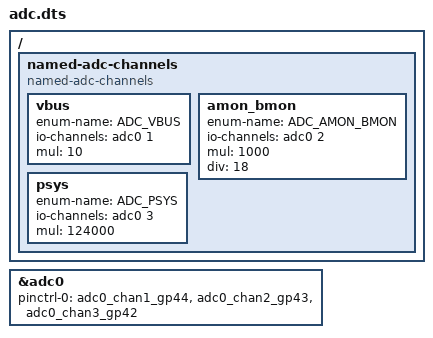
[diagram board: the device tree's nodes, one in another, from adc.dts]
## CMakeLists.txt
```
# Copyright 2021 The ChromiumOS Authors
# Use of this source code is governed by a BSD-style license that can be
# found in the LICENSE file.

cmake_minimum_required(VERSION 3.13.1)

find_package(Zephyr REQUIRED HINTS "${ZEPHYR_BASE}")

cros_ec_library_include_directories(include)

# Common Herobrine implementation
zephyr_library_sources(
  "src/board_chipset.c"
)

# Board specific implementation
zephyr_library_sources_ifdef(CONFIG_PLATFORM_EC_USBC
  "src/usbc_config.c"
  "src/usb_pd_policy.c")
zephyr_library_sources_ifdef(CONFIG_PLATFORM_EC_I2C
  "src/i2c.c")

if(DEFINED CONFIG_BOARD_EVOKER)
	project(evoker)
	zephyr_library_sources(
		"evoker/src/charger_override.c"
	)
elseif(DEFINED CONFIG_BOARD_HEROBRINE)
	project(herobrine)
	zephyr_library_sources_ifdef(CONFIG_PLATFORM_EC_USBC
	  "src/herobrine/alt_dev_replacement.c")
elseif(DEFINED CONFIG_BOARD_HOGLIN)
	project(hoglin)
elseif(DEFINED CONFIG_BOARD_VILLAGER)
	zephyr_library_sources(
		"villager/src/keyboard.c"
	)
	project(villager)
elseif(DEFINED CONFIG_BOARD_ZOGLIN)
	project(zoglin)
elseif(DEFINED CONFIG_BOARD_ZOMBIE)
	project(zombie)
endif()
```

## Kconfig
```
# Copyright 2022 The Chromium OS Authors. All rights reserved.
# Use of this source code is governed by a BSD-style license that can be
# found in the LICENSE file.

config BOARD_EVOKER
	bool "Evoker Board"
	help
	  Build the Evoker board. The board is based on the Herobrine
	  reference design.

config BOARD_HEROBRINE
	bool "Google Herobrine Baseboard"
	help
	  Build Google Herobrine reference board.  The board uses Nuvoton
	  NPCX9 chip as the EC.

config BOARD_HOGLIN
	bool "Qualcomm Hoglin Baseboard"
	help
	  Build Qualcomm Hoglin reference board.  The board uses Nuvoton
	  NPCX9 chip as the EC.

config BOARD_VILLAGER
	bool "Villager Board"
	help
	  Build the Villager board. The board is based on the Herobrine
	  reference design.

config BOARD_ZOGLIN
	bool "Qualcomm Zoglin Baseboard"
	help
	  Build Qualcomm Hoglin reference board.  The board uses Nuvoton
	  NPCX9 chip as the EC.

source "Kconfig.zephyr"
```

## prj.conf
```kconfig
# Copyright 2021 The ChromiumOS Authors
# Use of this source code is governed by a BSD-style license that can be
# found in the LICENSE file.

CONFIG_CROS_EC=y
CONFIG_SHIMMED_TASKS=y
CONFIG_PLATFORM_EC=y
CONFIG_PLATFORM_EC_BRINGUP=y
CONFIG_PLATFORM_EC_EXTPOWER_GPIO=y
CONFIG_PLATFORM_EC_SWITCH=y
CONFIG_PLATFORM_EC_LID_SWITCH=y
CONFIG_PLATFORM_EC_BACKLIGHT_LID=y
CONFIG_PLATFORM_EC_POWER_BUTTON=y
CONFIG_PLATFORM_EC_CBI_GPIO=y
CONFIG_KERNEL_SHELL=y
CONFIG_PLATFORM_EC_BOARD_RESET_AFTER_POWER_ON=y

# I2C options
CONFIG_I2C=y
CONFIG_PLATFORM_EC_CONSOLE_CMD_I2C_SPEED=y
CONFIG_PLATFORM_EC_HOSTCMD_I2C_CONTROL=y

# Shell history and tab autocompletion (for convenience)
CONFIG_SHELL_HELP=y
CONFIG_SHELL_HISTORY=y
CONFIG_SHELL_TAB=y
CONFIG_SHELL_TAB_AUTOCOMPLETION=y

# Application Processor is Qualcomm SC7280
CONFIG_AP_ARM_QUALCOMM_SC7280=y

# GPIO Switchcap
CONFIG_PLATFORM_EC_SWITCHCAP_GPIO=y

# Board version is selected over GPIO board ID pins.
CONFIG_PLATFORM_EC_BOARD_VERSION_GPIO=y

# Power Sequencing
CONFIG_PLATFORM_EC_POWERSEQ=y
CONFIG_PLATFORM_EC_POWERSEQ_HOST_SLEEP=y
CONFIG_PLATFORM_EC_POWERSEQ_PP5000_CONTROL=n
CONFIG_PLATFORM_EC_POWER_SLEEP_FAILURE_DETECTION=y
CONFIG_PLATFORM_EC_CHIPSET_RESET_HOOK=y
CONFIG_PLATFORM_EC_CHIPSET_RESUME_INIT_HOOK=y

# MKBP event
CONFIG_PLATFORM_EC_MKBP_EVENT=y
CONFIG_PLATFORM_EC_MKBP_USE_GPIO=y

# Keyboard
CONFIG_PLATFORM_EC_KEYBOARD=y
CONFIG_PLATFORM_EC_KEYBOARD_PROTOCOL_MKBP=y
CONFIG_PLATFORM_EC_MKBP_INPUT_DEVICES=y
CONFIG_PLATFORM_EC_KEYBOARD_COL2_INVERTED=y
CONFIG_PLATFORM_EC_KEYBOARD_REFRESH_ROW3=y
CONFIG_PLATFORM_EC_VOLUME_BUTTONS=y
CONFIG_PLATFORM_EC_CMD_BUTTON=y
CONFIG_CROS_KB_RAW_NPCX=y

# ADC
CONFIG_ADC=y
CONFIG_ADC_SHELL=n

# Battery
CONFIG_PLATFORM_EC_BATTERY=y
CONFIG_PLATFORM_EC_BATTERY_SMART=y
CONFIG_PLATFORM_EC_I2C_VIRTUAL_BATTERY=y
CONFIG_PLATFORM_EC_I2C_PASSTHRU_RESTRICTED=y
CONFIG_PLATFORM_EC_BATTERY_FUEL_GAUGE=y
CONFIG_PLATFORM_EC_BATTERY_CUT_OFF=y
CONFIG_PLATFORM_EC_BATTERY_PRESENT_GPIO=y
CONFIG_PLATFORM_EC_CHARGER_ISL9238C=y
CONFIG_PLATFORM_EC_CHARGE_RAMP_HW=y
CONFIG_PLATFORM_EC_USE_BATTERY_DEVICE_CHEMISTRY=y
CONFIG_PLATFORM_EC_BATTERY_DEVICE_CHEMISTRY="LION"
CONFIG_PLATFORM_EC_BATTERY_REVIVE_DISCONNECT=y
CONFIG_PLATFORM_EC_CHARGER_DISCHARGE_ON_AC=y
CONFIG_PLATFORM_EC_CHARGER_DISCHARGE_ON_AC_CHARGER=y
CONFIG_PLATFORM_EC_CHARGER_MIN_BAT_PCT_FOR_POWER_ON=2
CONFIG_PLATFORM_EC_CHARGER_MIN_POWER_MW_FOR_POWER_ON=12500
CONFIG_PLATFORM_EC_CHARGER_PROFILE_OVERRIDE=y
CONFIG_PLATFORM_EC_CHARGER_PSYS=y
CONFIG_PLATFORM_EC_CHARGER_PSYS_READ=y
CONFIG_PLATFORM_EC_CHARGER_SENSE_RESISTOR=10
CONFIG_PLATFORM_EC_CHARGER_SENSE_RESISTOR_AC=20
CONFIG_PLATFORM_EC_CONSOLE_CMD_CHARGER_ADC_AMON_BMON=y

# USB-A
CONFIG_PLATFORM_EC_USBA=y

# USB-C
CONFIG_PLATFORM_EC_USB_PD_FRS=y
CONFIG_PLATFORM_EC_BC12_DETECT_PI3USB9201=y
CONFIG_PLATFORM_EC_USB_PD_USB32_DRD=n
CONFIG_PLATFORM_EC_USBC_PPC_SYV682C=y
CONFIG_PLATFORM_EC_USB_PD_FRS_PPC=y
CONFIG_PLATFORM_EC_USBC_RETIMER_FW_UPDATE=n
CONFIG_PLATFORM_EC_USBC_SS_MUX_DFP_ONLY=y
CONFIG_PLATFORM_EC_USB_DRP_ACC_TRYSRC=y
CONFIG_PLATFORM_EC_USB_PD_5V_EN_CUSTOM=y
CONFIG_PLATFORM_EC_USB_PD_VBUS_DETECT_TCPC=y
CONFIG_PLATFORM_EC_USB_PD_DISCHARGE_PPC=y
CONFIG_PLATFORM_EC_USB_PD_DPS=y
CONFIG_PLATFORM_EC_USB_PD_REV30=y
CONFIG_PLATFORM_EC_USB_PD_TBT_COMPAT_MODE=n
CONFIG_PLATFORM_EC_USB_PD_USB4=n
CONFIG_PLATFORM_EC_USB_PD_TCPC_LOW_POWER=y
CONFIG_PLATFORM_EC_USB_PD_TCPM_PS8805=y
CONFIG_PLATFORM_EC_USB_PD_TCPC_RUNTIME_CONFIG=n
CONFIG_PLATFORM_EC_USB_MUX_RUNTIME_CONFIG=n
CONFIG_PLATFORM_EC_USB_PD_LOGGING=y
CONFIG_PLATFORM_EC_CONFIG_USB_PD_3A_PORTS=2

# USB ID
# This is allocated specifically for Herobrine
# http://google3/hardware/standards/usb/
# TODO(b/183608112): Move to device tree
CONFIG_PLATFORM_EC_USB_PID=0x5055

# RTC
CONFIG_PLATFORM_EC_RTC=y
CONFIG_CROS_RTC_NXP_PCF85063A=y
CONFIG_PLATFORM_EC_HOSTCMD_RTC=y
CONFIG_PLATFORM_EC_CONSOLE_CMD_RTC=y
CONFIG_PLATFORM_EC_CONSOLE_CMD_RTC_ALARM=y

# EC software sync
CONFIG_PLATFORM_EC_VBOOT_HASH=y

# Sensors
CONFIG_PLATFORM_EC_MOTIONSENSE=y
CONFIG_PLATFORM_EC_ACCEL_FIFO=y
CONFIG_PLATFORM_EC_ACCEL_SPOOF_MODE=y
CONFIG_PLATFORM_EC_CONSOLE_CMD_ACCELS=y
CONFIG_PLATFORM_EC_CONSOLE_CMD_ACCEL_INFO=y
CONFIG_PLATFORM_EC_GMR_TABLET_MODE=y
CONFIG_PLATFORM_EC_LID_ANGLE=y
CONFIG_PLATFORM_EC_LID_ANGLE_UPDATE=y
CONFIG_PLATFORM_EC_SENSOR_TIGHT_TIMESTAMPS=y
CONFIG_PLATFORM_EC_TABLET_MODE=y
CONFIG_PLATFORM_EC_TABLET_MODE_SWITCH=y
CONFIG_PLATFORM_EC_MAX_SENSOR_FREQ_MILLIHZ=100000

# Sensor Drivers
CONFIG_PLATFORM_EC_ACCEL_BMA255=y
CONFIG_PLATFORM_EC_ACCELGYRO_BMI260=y
CONFIG_PLATFORM_EC_ACCELGYRO_BMI_COMM_I2C=y

CONFIG_SYSCON=y
CONFIG_PLATFORM_EC_EMULATED_SYSRQ=y
```

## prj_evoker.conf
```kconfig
# Copyright 2022 The ChromiumOS Authors
# Use of this source code is governed by a BSD-style license that can be
# found in the LICENSE file.

# Evoker board-specific Kconfig settings.
CONFIG_BOARD_EVOKER=y

# Disable type-c port sourcing 3A
CONFIG_PLATFORM_EC_CONFIG_USB_PD_3A_PORTS=0

CONFIG_PLATFORM_EC_ACCEL_BMA255=n
CONFIG_PLATFORM_EC_ACCEL_BMA4XX=y

CONFIG_PLATFORM_EC_CONSOLE_CMD_CHARGER_DUMP=y
```

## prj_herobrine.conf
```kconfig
# Copyright 2022 The ChromiumOS Authors. All rights reserved.
# Use of this source code is governed by a BSD-style license that can be
# found in the LICENSE file.

# Herobrine-NPCX9 reference-board-specific Kconfig settings.
CONFIG_BOARD_HEROBRINE=y

# Sensors
CONFIG_PLATFORM_EC_ALS=y

# Sensor Drivers
CONFIG_PLATFORM_EC_ALS_TCS3400=y
CONFIG_PLATFORM_EC_ALS_TCS3400_EMULATED_IRQ_EVENT=y
```

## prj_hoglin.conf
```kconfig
# Copyright 2022 The ChromiumOS Authors. All rights reserved.
# Use of this source code is governed by a BSD-style license that can be
# found in the LICENSE file.

# Hoglin reference-board-specific Kconfig settings.
CONFIG_BOARD_HOGLIN=y
CONFIG_PLATFORM_EC_ACCEL_BMA255=n
CONFIG_PLATFORM_EC_ACCEL_BMA4XX=y

# Sensors
CONFIG_PLATFORM_EC_ALS=y

# Sensor Drivers
CONFIG_PLATFORM_EC_ALS_TCS3400=y
CONFIG_PLATFORM_EC_ALS_TCS3400_EMULATED_IRQ_EVENT=y
```

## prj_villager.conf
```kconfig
# Copyright 2022 The ChromiumOS Authors. All rights reserved.
# Use of this source code is governed by a BSD-style license that can be
# found in the LICENSE file.

# Villager board-specific Kconfig settings.
CONFIG_BOARD_VILLAGER=y

CONFIG_PLATFORM_EC_ACCEL_KX022=y
```

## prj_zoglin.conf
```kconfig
# Copyright 2022 The ChromiumOS Authors.
# Use of this source code is governed by a BSD-style license that can be
# found in the LICENSE file.

# Hoglin reference-board-specific Kconfig settings.
CONFIG_BOARD_ZOGLIN=y
CONFIG_PLATFORM_EC_ACCEL_BMA255=n
CONFIG_PLATFORM_EC_ACCEL_BMA4XX=y

# Sensors
CONFIG_PLATFORM_EC_ALS=y

# Sensor Drivers
CONFIG_PLATFORM_EC_ALS_TCS3400=y
CONFIG_PLATFORM_EC_ALS_TCS3400_EMULATED_IRQ_EVENT=y
```

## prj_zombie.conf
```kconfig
# Copyright 2022 The ChromiumOS Authors
# Use of this source code is governed by a BSD-style license that can be
# found in the LICENSE file.

# Villager board-specific Kconfig settings.
CONFIG_BOARD_ZOMBIE=y

CONFIG_PLATFORM_EC_ACCEL_KX022=y
```

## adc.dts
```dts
/* Copyright 2022 The ChromiumOS Authors. All rights reserved.
 * Use of this source code is governed by a BSD-style license that can be
 * found in the LICENSE file.
 */

#include <zephyr/dt-bindings/adc/adc.h>

/ {
	named-adc-channels {
		compatible = "named-adc-channels";

		vbus {
			enum-name = "ADC_VBUS";
			io-channels = <&adc0 1>;
			/* Measure VBUS through a 1/10 voltage divider */
			mul = <10>;
		};
		amon_bmon {
			enum-name = "ADC_AMON_BMON";
			io-channels = <&adc0 2>;
			/*
			 * Adapter current output or battery charging/
			 * discharging current (uV) 18x amplification on
			 * charger side.
			 */
			mul = <1000>;
			div = <18>;
		};
		psys {
			enum-name = "ADC_PSYS";
			io-channels = <&adc0 3>;
			/*
			 * ISL9238 PSYS output is 1.44 uA/W over 5.6K resistor,
			 * to read 0.8V @ 99 W, i.e. 124000 uW/mV.
			 */
			mul = <124000>;
		};
	};
};

&adc0 {
	status = "okay";
	pinctrl-0 = <&adc0_chan1_gp44
		     &adc0_chan2_gp43
		     &adc0_chan3_gp42>;
	pinctrl-names = "default";
};
```

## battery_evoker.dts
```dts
/* Copyright 2022 The ChromiumOS Authors
 * Use of this source code is governed by a BSD-style license that can be
 * found in the LICENSE file.
 */

/ {
	batteries {
		default_battery: pc_vp_bp153 {
			compatible = "smp,pc-vp-bp153", "battery-smart";
		};
		pc-vp-bp144 {
			compatible = "smp,pc-vp-bp144", "battery-smart";
		};
		ap16l5j {
			compatible = "panasonic,ap16l5j", "battery-smart";
		};
	};
};
```

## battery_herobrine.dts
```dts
/* Copyright 2021 The ChromiumOS Authors. All rights reserved.
 * Use of this source code is governed by a BSD-style license that can be
 * found in the LICENSE file.
 */

/ {
	batteries {
		default_battery: ap16l5j {
			compatible = "panasonic,ap16l5j", "battery-smart";
		};
	};
};
```

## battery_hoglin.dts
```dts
/* Copyright 2022 The ChromiumOS Authors. All rights reserved.
 * Use of this source code is governed by a BSD-style license that can be
 * found in the LICENSE file.
 */

/ {
	batteries {
		default_battery: 7c01 {
			compatible = "ganfeng,7c01", "battery-smart";
		};
	};
};
```

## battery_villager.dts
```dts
/* Copyright 2022 The ChromiumOS Authors. All rights reserved.
 * Use of this source code is governed by a BSD-style license that can be
 * found in the LICENSE file.
 */

/ {
	batteries {
		default_battery: ap19a5k {
			compatible = "panasonic,ap19a5k", "battery-smart";
		};
		ap19a8k {
			compatible = "lgc,ap19a8k", "battery-smart";
		};
	};
};
```

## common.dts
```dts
/* Copyright 2022 The Chromium OS Authors. All rights reserved.
 * Use of this source code is governed by a BSD-style license that can be
 * found in the LICENSE file.
 */

#include <dt-bindings/wake_mask_event_defines.h>

/ {
	chosen {
		cros,rtc = &pcf85063a;
		zephyr,ec-host-interface = &shi0;
	};

	ec-console {
		compatible = "ec-console";
		disabled = "hostcmd";
	};

	ec-mkbp-host-event-wakeup-mask {
		compatible = "ec-wake-mask-event";
		wakeup-mask = <(
			HOST_EVENT_LID_OPEN |
			HOST_EVENT_POWER_BUTTON |
			HOST_EVENT_AC_CONNECTED |
			HOST_EVENT_AC_DISCONNECTED |
			HOST_EVENT_HANG_DETECT |
			HOST_EVENT_RTC |
			HOST_EVENT_MODE_CHANGE |
			HOST_EVENT_DEVICE)>;
	};

	ec-mkbp-event-wakeup-mask {
		compatible = "ec-wake-mask-event";
		wakeup-mask = <(MKBP_EVENT_KEY_MATRIX | \
				MKBP_EVENT_HOST_EVENT | \
				MKBP_EVENT_SENSOR_FIFO)>;
	};
};

&shi0 {
	status = "okay";
	pinctrl-0 = <&shi_gp46_47_53_55>;
	pinctrl-1 = <&shi_gpio_gp46_47_53_55>;
	pinctrl-names = "default", "sleep";
};
```

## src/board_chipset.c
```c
/* Copyright 2022 The ChromiumOS Authors.
 * Use of this source code is governed by a BSD-style license that can be
 * found in the LICENSE file.
 */

/* Herobrine chipset-specific configuration */

#include "common.h"
#include "battery.h"
#include "gpio.h"
#include "hooks.h"
#include "timer.h"
#include "usb_pd.h"

#define CPRINTS(format, args...) cprints(CC_CHIPSET, format, ##args)
#define CPRINTF(format, args...) cprintf(CC_CHIPSET, format, ##args)

/*
 * A window of PD negotiation. It starts from the Type-C state reaching
 * Attached.SNK, and ends when the PD contract is created. The VBUS may be
 * raised anytime in this window.
 *
 * The current implementation is the worst case scenario: every message the PD
 * negotiation is received at the last moment before timeout. More extra time
 * is added to compensate the delay internally, like the decision of the DPM.
 *
 * TODO(waihong): Cancel this timer when the PD contract is negotiated.
 */
#define PD_READY_TIMEOUT                                                    \
	(PD_T_SINK_WAIT_CAP + PD_T_SENDER_RESPONSE + PD_T_SINK_TRANSITION + \
	 20 * MSEC)

#define PD_READY_POLL_DELAY (10 * MSEC)

static timestamp_t pd_ready_timeout;

static bool pp5000_inited;

/* Called on USB PD connected */
static void board_usb_pd_connect(void)
{
	int soc = -1;

	/* First boot, battery unattached or low SOC */
	if (!pp5000_inited &&
	    ((battery_state_of_charge_abs(&soc) != EC_SUCCESS ||
	      soc < CONFIG_CHARGER_MIN_BAT_PCT_FOR_POWER_ON))) {
		pd_ready_timeout = get_time();
		pd_ready_timeout.val += PD_READY_TIMEOUT;
	}
}
DECLARE_HOOK(HOOK_USB_PD_CONNECT, board_usb_pd_connect, HOOK_PRIO_DEFAULT);

static void wait_pd_ready(void)
{
	CPRINTS("Wait PD negotiated VBUS transition %u",
		pd_ready_timeout.le.lo);
	while (pd_ready_timeout.val && get_time().val < pd_ready_timeout.val)
		usleep(PD_READY_POLL_DELAY);
}

/* Called on AP S5 -> S3 transition */
static void board_chipset_pre_init(void)
{
	if (!pp5000_inited) {
		wait_pd_ready();
		CPRINTS("Enable 5V rail");
		gpio_pin_set_dt(GPIO_DT_FROM_NODELABEL(gpio_en_pp5000_s5), 1);
		pp5000_inited = true;
	}
}
DECLARE_HOOK(HOOK_CHIPSET_PRE_INIT, board_chipset_pre_init, HOOK_PRIO_DEFAULT);
```

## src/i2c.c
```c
/* Copyright 2021 The ChromiumOS Authors. All rights reserved.
 * Use of this source code is governed by a BSD-style license that can be
 * found in the LICENSE file.
 */

#include "i2c/i2c.h"
#include "i2c.h"

/* Herobrine-NPCX9 board specific i2c implementation */

#ifdef CONFIG_PLATFORM_EC_I2C_PASSTHRU_RESTRICTED
int board_allow_i2c_passthru(const struct i2c_cmd_desc_t *cmd_desc)
{
	return (i2c_get_device_for_port(cmd_desc->port) ==
		i2c_get_device_for_port(I2C_PORT_VIRTUAL_BATTERY));
}
#endif
```

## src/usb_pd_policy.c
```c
/* Copyright 2021 The ChromiumOS Authors. All rights reserved.
 * Use of this source code is governed by a BSD-style license that can be
 * found in the LICENSE file.
 */

#include <zephyr/drivers/gpio.h>

#include "charge_manager.h"
#include "chipset.h"
#include "console.h"
#include "system.h"
#include "usb_mux.h"
#include "usbc_ppc.h"
#include "util.h"

#define CPRINTS(format, args...) cprints(CC_USBCHARGE, format, ##args)
#define CPRINTF(format, args...) cprintf(CC_USBCHARGE, format, ##args)

int pd_check_vconn_swap(int port)
{
	/* In G3, do not allow vconn swap since PP5000 rail is off */
	return gpio_pin_get_dt(GPIO_DT_FROM_NODELABEL(gpio_en_pp5000_s5));
}

static uint8_t vbus_en[CONFIG_USB_PD_PORT_MAX_COUNT];

static void board_vbus_update_source_current(int port)
{
	ppc_vbus_source_enable(port, vbus_en[port]);
}

void pd_power_supply_reset(int port)
{
	int prev_en;

	prev_en = vbus_en[port];

	/* Disable VBUS */
	vbus_en[port] = 0;
	board_vbus_update_source_current(port);

	/* Enable discharge if we were previously sourcing 5V */
	if (prev_en)
		pd_set_vbus_discharge(port, 1);

	/* notify host of power info change */
	pd_send_host_event(PD_EVENT_POWER_CHANGE);
}

int pd_set_power_supply_ready(int port)
{
	/* Disable charging */
	board_vbus_sink_enable(port, 0);

	pd_set_vbus_discharge(port, 0);

	/* Provide VBUS */
	vbus_en[port] = 1;
	board_vbus_update_source_current(port);

	/* notify host of power info change */
	pd_send_host_event(PD_EVENT_POWER_CHANGE);

	return EC_SUCCESS; /* we are ready */
}

int board_vbus_source_enabled(int port)
{
	return vbus_en[port];
}

int pd_snk_is_vbus_provided(int port)
{
	return tcpm_check_vbus_level(port, VBUS_PRESENT);
}

/* ----------------- Vendor Defined Messages ------------------ */
#ifdef CONFIG_USB_PD_ALT_MODE_DFP
__override int svdm_dp_config(int port, uint32_t *payload)
{
	int opos = pd_alt_mode(port, TCPCI_MSG_SOP, USB_SID_DISPLAYPORT);
	uint8_t pin_mode = get_dp_pin_mode(port);

	if (!pin_mode)
		return 0;

	/*
	 * Defer setting the usb_mux until HPD goes high, svdm_dp_attention().
	 * The AP only supports one DP phy. An external DP mux switches between
	 * the two ports. Should switch those muxes when it is really used,
	 * i.e. HPD high; otherwise, the real use case is preempted, like:
	 *  (1) plug a dongle without monitor connected to port-0,
	 *  (2) plug a dongle without monitor connected to port-1,
	 *  (3) plug a monitor to the port-1 dongle.
	 */

	payload[0] =
		VDO(USB_SID_DISPLAYPORT, 1, CMD_DP_CONFIG | VDO_OPOS(opos));
	payload[1] = VDO_DP_CFG(pin_mode, /* pin mode */
				1, /* DPv1.3 signaling */
				2); /* UFP connected */
	return 2;
};

__override void svdm_dp_post_config(int port)
{
	dp_flags[port] |= DP_FLAGS_DP_ON;
}

/**
 * Is the port fine to be muxed its DisplayPort lines?
 *
 * Only one port can be muxed to DisplayPort at a time.
 *
 * @param port	Port number of TCPC.
 * @return	1 is fine; 0 is bad as other port is already muxed;
 */
static int is_dp_muxable(int port)
{
	int i;

	for (i = 0; i < CONFIG_USB_PD_PORT_MAX_COUNT; i++)
		if (i != port) {
			if (usb_mux_get(i) & USB_PD_MUX_DP_ENABLED)
				return 0;
		}

	return 1;
}

__override int svdm_dp_attention(int port, uint32_t *payload)
{
	const struct gpio_dt_spec *hpd =
		GPIO_DT_FROM_NODELABEL(gpio_dp_hot_plug_det_r);
	int lvl = PD_VDO_DPSTS_HPD_LVL(payload[1]);
	int irq = PD_VDO_DPSTS_HPD_IRQ(payload[1]);
	int cur_lvl = gpio_pin_get_dt(hpd);
	mux_state_t mux_state;

	dp_status[port] = payload[1];

	if (!is_dp_muxable(port)) {
		/* TODO(waihong): Info user? */
		CPRINTS("p%d: The other port is already muxed.", port);
		return 0;
	}

	/*
	 * Initial implementation to handle HPD. Only the first-plugged port
	 * works, i.e. sending HPD signal to AP. The second-plugged port
	 * will be ignored.
	 *
	 * TODO(waihong): Continue the above case, if the first-plugged port
	 * is then unplugged, switch to the second-plugged port and signal AP?
	 */
	if (lvl) {
		/*
		 * Enable and switch the DP port selection mux to the
		 * correct port.
		 *
		 * TODO(waihong): Better to move switching DP mux to
		 * the usb_mux abstraction.
		 */
		gpio_pin_set_dt(GPIO_DT_FROM_NODELABEL(gpio_dp_mux_sel),
				port == 1);
		gpio_pin_set_dt(GPIO_DT_FROM_NODELABEL(gpio_dp_mux_oe_l), 0);

		/* Connect the SBU lines in PPC chip. */
		if (IS_ENABLED(CONFIG_USBC_PPC_SBU))
			ppc_set_sbu(port, 1);

		/*
		 * Connect the USB SS/DP lines in TCPC chip.
		 *
		 * When mf_pref not true, still use the dock muxing
		 * because of the board USB-C topology (limited to 2
		 * lanes DP).
		 */
		usb_mux_set(port, USB_PD_MUX_DOCK, USB_SWITCH_CONNECT,
			    polarity_rm_dts(pd_get_polarity(port)));
	} else {
		/* Disconnect the DP port selection mux. */
		gpio_pin_set_dt(GPIO_DT_FROM_NODELABEL(gpio_dp_mux_oe_l), 1);
		gpio_pin_set_dt(GPIO_DT_FROM_NODELABEL(gpio_dp_mux_sel), 0);

		/* Disconnect the SBU lines in PPC chip. */
		if (IS_ENABLED(CONFIG_USBC_PPC_SBU))
			ppc_set_sbu(port, 0);

		/* Disconnect the DP but keep the USB SS lines in TCPC chip. */
		usb_mux_set(port, USB_PD_MUX_USB_ENABLED, USB_SWITCH_CONNECT,
			    polarity_rm_dts(pd_get_polarity(port)));
	}

	if (chipset_in_state(CHIPSET_STATE_ANY_SUSPEND) && (irq || lvl))
		/*
		 * Wake up the AP.  IRQ or level high indicates a DP sink is now
		 * present.
		 */
		pd_notify_dp_alt_mode_entry(port);

	/* Configure TCPC for the HPD event, for proper muxing */
	mux_state = (lvl ? USB_PD_MUX_HPD_LVL : USB_PD_MUX_HPD_LVL_DEASSERTED) |
		    (irq ? USB_PD_MUX_HPD_IRQ : USB_PD_MUX_HPD_IRQ_DEASSERTED);
	usb_mux_hpd_update(port, mux_state);

	/* Signal AP for the HPD event, through GPIO to AP */
	if (irq & cur_lvl) {
		uint64_t now = get_time().val;
		/* Wait for the minimum spacing between IRQ_HPD if needed */
		if (now < svdm_hpd_deadline[port])
			usleep(svdm_hpd_deadline[port] - now);

		/* Generate IRQ_HPD pulse */
		CPRINTS("C%d: Recv IRQ. HPD->0", port);
		gpio_pin_set_dt(hpd, 0);
		usleep(HPD_DSTREAM_DEBOUNCE_IRQ);
		gpio_pin_set_dt(hpd, 1);
		CPRINTS("C%d: Recv IRQ. HPD->1", port);

		/* Set the minimum time delay (2ms) for the next HPD IRQ */
		svdm_hpd_deadline[port] =
			get_time().val + HPD_USTREAM_DEBOUNCE_LVL;
	} else if (irq & !lvl) {
		CPRINTF("ERR:HPD:IRQ&LOW\n");
		return 0;
	} else {
		CPRINTS("C%d: Recv lvl. HPD->%d", port, lvl);
		gpio_pin_set_dt(hpd, lvl);
		/* Set the minimum time delay (2ms) for the next HPD IRQ */
		svdm_hpd_deadline[port] =
			get_time().val + HPD_USTREAM_DEBOUNCE_LVL;
	}

	return 1;
}

__override void svdm_exit_dp_mode(int port)
{
	CPRINTS("%s(%d)", __func__, port);
	if (is_dp_muxable(port)) {
		/* Disconnect the DP port selection mux. */
		gpio_pin_set_dt(GPIO_DT_FROM_NODELABEL(gpio_dp_mux_oe_l), 1);
		gpio_pin_set_dt(GPIO_DT_FROM_NODELABEL(gpio_dp_mux_sel), 0);

		/* Signal AP for the HPD low event */
		usb_mux_hpd_update(port, USB_PD_MUX_HPD_LVL_DEASSERTED |
						 USB_PD_MUX_HPD_IRQ_DEASSERTED);
		CPRINTS("C%d: DP exit. HPD->0", port);
		gpio_pin_set_dt(GPIO_DT_FROM_NODELABEL(gpio_dp_hot_plug_det_r),
				0);
	}
}
#endif /* CONFIG_USB_PD_ALT_MODE_DFP */
```

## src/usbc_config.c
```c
/* Copyright 2021 The ChromiumOS Authors
 * Use of this source code is governed by a BSD-style license that can be
 * found in the LICENSE file.
 */

/* Herobrine board-specific USB-C configuration */

#include <zephyr/drivers/gpio.h>

#include "charger.h"
#include "charger/isl923x_public.h"
#include "charge_manager.h"
#include "charge_state.h"
#include "common.h"
#include "config.h"
#include "cros_board_info.h"
#include "gpio/gpio_int.h"
#include "hooks.h"
#include "ppc/sn5s330_public.h"
#include "ppc/syv682x_public.h"
#include "system.h"
#include "tcpm/ps8xxx_public.h"
#include "tcpm/tcpci.h"
#include "timer.h"
#include "usb_pd.h"
#include "usb_mux.h"
#include "usbc_ocp.h"
#include "usbc_ppc.h"
#include "usbc/ppc.h"

#define CPRINTS(format, args...) cprints(CC_USBCHARGE, format, ##args)
#define CPRINTF(format, args...) cprintf(CC_USBCHARGE, format, ##args)

#ifdef CONFIG_PLATFORM_EC_USBA
static void usba_oc_deferred(void)
{
	/* Use next number after all USB-C ports to indicate the USB-A port */
	board_overcurrent_event(
		CONFIG_USB_PD_PORT_MAX_COUNT,
		!gpio_pin_get_dt(GPIO_DT_FROM_NODELABEL(gpio_usb_a0_oc_odl)));
}
DECLARE_DEFERRED(usba_oc_deferred);

void usba_oc_interrupt(enum gpio_signal signal)
{
	hook_call_deferred(&usba_oc_deferred_data, 0);
}

void ppc_interrupt(enum gpio_signal signal)
{
	switch (signal) {
	case GPIO_USB_C0_SWCTL_INT_ODL:
		ppc_chips[0].drv->interrupt(0);
		break;

	case GPIO_USB_C1_SWCTL_INT_ODL:
		ppc_chips[1].drv->interrupt(1);
		break;

	default:
		break;
	}
}

__overridable int board_charger_profile_override(struct charge_state_data *curr)
{
	return EC_SUCCESS;
}

int charger_profile_override(struct charge_state_data *curr)
{
	int usb_mv;
	int port;

	if (curr->state != ST_CHARGE)
		return 0;

	/* Lower the max requested voltage to 5V when battery is full. */
	if (chipset_in_state(CHIPSET_STATE_ANY_OFF) &&
	    !(curr->batt.flags & BATT_FLAG_BAD_STATUS) &&
	    !(curr->batt.flags & BATT_FLAG_WANT_CHARGE) &&
	    (curr->batt.status & STATUS_FULLY_CHARGED))
		usb_mv = 5000;
	else
		usb_mv = PD_MAX_VOLTAGE_MV;

	if (pd_get_max_voltage() != usb_mv) {
		CPRINTS("VBUS limited to %dmV", usb_mv);
		for (port = 0; port < CONFIG_USB_PD_PORT_MAX_COUNT; port++)
			pd_set_external_voltage_limit(port, usb_mv);
	}

	board_charger_profile_override(curr);

	return 0;
}

enum ec_status charger_profile_override_get_param(uint32_t param,
						  uint32_t *value)
{
	return EC_RES_INVALID_PARAM;
}

enum ec_status charger_profile_override_set_param(uint32_t param,
						  uint32_t value)
{
	return EC_RES_INVALID_PARAM;
}

/* Initialize board USC-C things */
static void board_init_usbc(void)
{
	/* Enable USB-A overcurrent interrupt */
	gpio_enable_dt_interrupt(GPIO_INT_FROM_NODELABEL(int_usb_a0_oc));
}
DECLARE_HOOK(HOOK_INIT, board_init_usbc, HOOK_PRIO_DEFAULT);

void board_tcpc_init(void)
{
	/* Only reset TCPC if not sysjump */
	if (!system_jumped_late()) {
		/* TODO(crosbug.com/p/61098): How long do we need to wait? */
		board_reset_pd_mcu();
	}

	/* Enable PPC interrupts */
	gpio_enable_dt_interrupt(GPIO_INT_FROM_NODELABEL(int_usb_c0_swctl));

	/* Enable TCPC interrupts */
	gpio_enable_dt_interrupt(GPIO_INT_FROM_NODELABEL(int_usb_c0_pd));
	gpio_enable_dt_interrupt(GPIO_INT_FROM_NODELABEL(int_usb_c1_pd));

	/*
	 * Initialize HPD to low; after sysjump SOC needs to see
	 * HPD pulse to enable video path
	 */
	for (int port = 0; port < CONFIG_USB_PD_PORT_MAX_COUNT; ++port)
		usb_mux_hpd_update(port, USB_PD_MUX_HPD_LVL_DEASSERTED |
						 USB_PD_MUX_HPD_IRQ_DEASSERTED);
}
DECLARE_HOOK(HOOK_INIT, board_tcpc_init, HOOK_PRIO_POST_I2C);

void board_reset_pd_mcu(void)
{
	cprints(CC_USB, "Resetting TCPCs...");
	cflush();

	gpio_pin_set_dt(GPIO_DT_FROM_NODELABEL(gpio_usb_c0_pd_rst_l), 0);
	gpio_pin_set_dt(GPIO_DT_FROM_NODELABEL(gpio_usb_c1_pd_rst_l), 0);
	msleep(PS8XXX_RESET_DELAY_MS);
	gpio_pin_set_dt(GPIO_DT_FROM_NODELABEL(gpio_usb_c0_pd_rst_l), 1);
	gpio_pin_set_dt(GPIO_DT_FROM_NODELABEL(gpio_usb_c1_pd_rst_l), 1);
	msleep(PS8805_FW_INIT_DELAY_MS);
}

void board_set_tcpc_power_mode(int port, int mode)
{
	/* Ignore the "mode" to turn the chip on.  We can only do a reset. */
	if (mode)
		return;

	board_reset_pd_mcu();
}

int board_vbus_sink_enable(int port, int enable)
{
	/* Both ports are controlled by PPC SN5S330 */
	return ppc_vbus_sink_enable(port, enable);
}

int board_is_sourcing_vbus(int port)
{
	/* Both ports are controlled by PPC SN5S330 */
	return ppc_is_sourcing_vbus(port);
}

void board_overcurrent_event(int port, int is_overcurrented)
{
	/* TODO(b/120231371): Notify AP */
	CPRINTS("p%d: overcurrent!", port);
}

int board_set_active_charge_port(int port)
{
	int is_real_port = (port >= 0 && port < CONFIG_USB_PD_PORT_MAX_COUNT);
	int i;

	if (!is_real_port && port != CHARGE_PORT_NONE)
		return EC_ERROR_INVAL;

	if (port == CHARGE_PORT_NONE) {
		CPRINTS("Disabling all charging port");

		/* Disable all ports. */
		for (i = 0; i < CONFIG_USB_PD_PORT_MAX_COUNT; i++) {
			/*
			 * Do not return early if one fails otherwise we can
			 * get into a boot loop assertion failure.
			 */
			if (board_vbus_sink_enable(i, 0))
				CPRINTS("Disabling p%d sink path failed.", i);
		}

		return EC_SUCCESS;
	}

	/* Check if the port is sourcing VBUS. */
	if (board_is_sourcing_vbus(port)) {
		CPRINTS("Skip enable p%d", port);
		return EC_ERROR_INVAL;
	}

	CPRINTS("New charge port: p%d", port);

	/*
	 * Turn off the other ports' sink path FETs, before enabling the
	 * requested charge port.
	 */
	for (i = 0; i < CONFIG_USB_PD_PORT_MAX_COUNT; i++) {
		if (i == port)
			continue;

		if (board_vbus_sink_enable(i, 0))
			CPRINTS("p%d: sink path disable failed.", i);
	}

	/* Enable requested charge port. */
	if (board_vbus_sink_enable(port, 1)) {
		CPRINTS("p%d: sink path enable failed.", port);
		return EC_ERROR_UNKNOWN;
	}

	return EC_SUCCESS;
}

void board_set_charge_limit(int port, int supplier, int charge_ma, int max_ma,
			    int charge_mv)
{
	/*
	 * Ignore lower charge ceiling on PD transition if our battery is
	 * critical, as we may brownout.
	 */
	if (supplier == CHARGE_SUPPLIER_PD && charge_ma < 1500 &&
	    charge_get_percent() < CONFIG_CHARGER_MIN_BAT_PCT_FOR_POWER_ON) {
		CPRINTS("Using max ilim %d", max_ma);
		charge_ma = max_ma;
	}

	charge_set_input_current_limit(
		MAX(charge_ma, CONFIG_CHARGER_INPUT_CURRENT), charge_mv);
}

uint16_t tcpc_get_alert_status(void)
{
	uint16_t status = 0;

	if (!gpio_pin_get_dt(GPIO_DT_FROM_NODELABEL(gpio_usb_c0_pd_int_odl)))
		if (gpio_pin_get_dt(
			    GPIO_DT_FROM_NODELABEL(gpio_usb_c0_pd_rst_l)))
			status |= PD_STATUS_TCPC_ALERT_0;
	if (!gpio_pin_get_dt(GPIO_DT_FROM_NODELABEL(gpio_usb_c1_pd_int_odl)))
		if (gpio_pin_get_dt(
			    GPIO_DT_FROM_NODELABEL(gpio_usb_c1_pd_rst_l)))
			status |= PD_STATUS_TCPC_ALERT_1;

	return status;
}
```

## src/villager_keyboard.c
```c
/* Copyright 2022 The Chromium OS Authors. All rights reserved.
 * Use of this source code is governed by a BSD-style license that can be
 * found in the LICENSE file.
 */

#include "common.h"
#include "hooks.h"
#include "keyboard_8042_sharedlib.h"
#include "keyboard_scan.h"
#include "timer.h"

/* Keyboard scan setting */
__override struct keyboard_scan_config keyscan_config = {
	/* Increase from 50 us, because KSO_02 passes through the H1. */
	.output_settle_us = 80,
	/* Other values should be the same as the default configuration. */
	.debounce_down_us = 9 * MSEC,
	.debounce_up_us = 30 * MSEC,
	.scan_period_us = 3 * MSEC,
	.min_post_scan_delay_us = 1000,
	.poll_timeout_us = 100 * MSEC,
	.actual_key_mask = {
		0x1c, 0xff, 0xff, 0xff, 0xff, 0xff, 0xff,
		0x86, 0xff, 0xff, 0x55, 0xff, 0xff, 0xff, 0xff  /* full set */
	},
};

static uint16_t villager_scancode_set2[KEYBOARD_COLS_MAX][KEYBOARD_ROWS] = {
	{0x0000, 0x0000, 0x0014, 0xe01f, 0xe014, 0xe007, 0x0000, 0x0000},
	{0x001f, 0x0076, 0x001f, 0x000e, 0x001c, 0x003a, 0x000d, 0x0016},
	{0x001f, 0x000c, 0x0004, 0x0006, 0x0005, 0x001f, 0x0026, 0x002a},
	{0x0032, 0x0034, 0x002c, 0x002e, 0x002b, 0x0029, 0x0025, 0x002d},
	{0x001f, 0x0009, 0x0083, 0x000b, 0x0003, 0x004c, 0x001e, 0x001d},
	{0x0051, 0x0000, 0x005b, 0x0000, 0x0042, 0x0022, 0x003e, 0x0043},
	{0x0031, 0x0033, 0x0035, 0x0036, 0x003b, 0x001b, 0x003e, 0x003c},
	{0x0000, 0x0012, 0x0061, 0x0000, 0x0000, 0x0000, 0x0000, 0x0059},
	{0x0055, 0x0052, 0x0054, 0x004e, 0x004c, 0x0024, 0x0044, 0x004d},
	{0x0045, 0x0001, 0x000a, 0x002f, 0x0043, 0x0049, 0x0046, 0x001a},
	{0xe011, 0x0000, 0x006a, 0x0000, 0x005d, 0x0000, 0x0011, 0x0000},
	{0x001f, 0x005d, 0xe075, 0x001f, 0x005a, 0xe072, 0x004a, 0x0066},
	{0xe06b, 0xe074, 0x001f, 0x0067, 0x001f, 0x0064, 0x0015, 0x001f},
	{0x001f, 0x001f, 0x001f, 0x001f, 0x001f, 0x001f, 0x001f, 0x0021},
	{0x0023, 0x001f, 0x001f, 0x001f, 0x001f, 0x001f, 0x001f, 0x001f},
};

#ifdef CONFIG_KEYBOARD_FACTORY_TEST
/*
 * Map keyboard connector pins to EC GPIO pins for factory test.
 * Pins mapped to {-1, -1} are skipped.
 * The connector has 24 pins total, and there is no pin 0.
 */
const int keyboard_factory_scan_pins[][2] = {
	{-1, -1}, {0, 5}, {1, 1}, {1, 0}, {0, 6},
	{0, 7}, {-1, -1}, {-1, -1}, {1, 4}, {1, 3},
	{-1, -1}, {1, 6}, {1, 7}, {3, 1}, {2, 0},
	{1, 5}, {2, 6}, {2, 7}, {2, 1}, {2, 4},
	{2, 5}, {1, 2}, {2, 3}, {2, 2}, {3, 0},
	{-1, -1}, {-1, -1}, {-1, -1}, {-1, -1}, {-1, -1},
	{-1, -1},
};

const int keyboard_factory_scan_pins_used =
			ARRAY_SIZE(keyboard_factory_scan_pins);
#endif

static const struct ec_response_keybd_config villager_keyboard = {
	.num_top_row_keys = 10,
	.action_keys = {
		TK_BACK,        /* T1 */
		TK_REFRESH,     /* T2 */
		TK_FULLSCREEN,      /* T3 */
		TK_OVERVIEW,        /* T4 */
		TK_SNAPSHOT,        /* T5 */
		TK_BRIGHTNESS_DOWN, /* T6 */
		TK_BRIGHTNESS_UP,   /* T7 */
		TK_VOL_MUTE,        /* T8 */
		TK_VOL_DOWN,        /* T9 */
		TK_VOL_UP,      /* T10 */
	},
	.capabilities = KEYBD_CAP_SCRNLOCK_KEY
};

__override const struct ec_response_keybd_config
*board_vivaldi_keybd_config(void)
{
	return &villager_keyboard;
}
#endif


static void keyboard_init(void)
{
	register_scancode_set2((uint16_t **) villager_scancode_set2,
				sizeof(villager_scancode_set2));
}
DECLARE_HOOK(HOOK_INIT, keyboard_init, HOOK_PRIO_DEFAULT);
```
